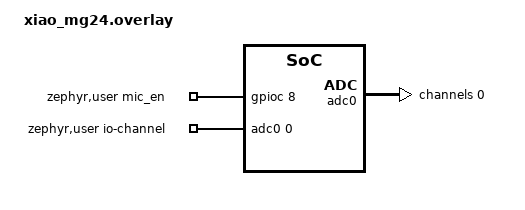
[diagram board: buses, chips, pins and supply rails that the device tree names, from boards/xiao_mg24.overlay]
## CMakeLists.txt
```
cmake_minimum_required(VERSION 3.20.0)
find_package(Zephyr REQUIRED HINTS $ENV{ZEPHYR_BASE})

project(adc_02)

target_sources(app PRIVATE src/main.c)
```

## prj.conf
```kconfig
CONFIG_GPIO=y
CONFIG_ADC=y

CONFIG_PRINTK=y
CONFIG_CONSOLE=y
CONFIG_SERIAL=y
```

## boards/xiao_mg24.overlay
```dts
/ {
    zephyr,user {
        io-channels = <&adc0 0>;
        mic_en_gpios = <&gpioc 8 GPIO_ACTIVE_HIGH>;
    };
};

&adc0 {
    status = "okay";
    #address-cells = <1>;
    #size-cells = <0>;

    channel@0 {
        reg = <0>;
        zephyr,acquisition-time = <ADC_ACQ_TIME_DEFAULT>;
        zephyr,gain = "ADC_GAIN_1";
        zephyr,input-positive = <IADC_INPUT_PC9>;
        zephyr,reference = "ADC_REF_VDD_1";
        zephyr,resolution = <12>;
        zephyr,vref-mv = <3300>;
    };
};
```

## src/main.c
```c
#include <zephyr/kernel.h>
#include <zephyr/device.h>
#include <zephyr/drivers/gpio.h>
#include <zephyr/drivers/adc.h>
#include <zephyr/sys/printk.h>

#define USER_NODE DT_PATH(zephyr_user)

#if !DT_NODE_EXISTS(USER_NODE)
#error "zephyr,user node missing"
#endif

static const struct gpio_dt_spec mic_en = GPIO_DT_SPEC_GET(USER_NODE, mic_en_gpios);
static const struct adc_dt_spec  mic_adc = ADC_DT_SPEC_GET(USER_NODE);

int main(void)
{
    int ret;
    int32_t mv;
    int16_t sample_buf;

    printk("\n--- Analog MIC (ADC) example ---\n");

    if (!device_is_ready(mic_en.port)) {
        printk("MIC_EN GPIO not ready\n");
        return 0;
    }

    if (!adc_is_ready_dt(&mic_adc)) {
        printk("ADC not ready\n");
        return 0;
    }

    ret = gpio_pin_configure_dt(&mic_en, GPIO_OUTPUT_INACTIVE);
    if (ret) {
        printk("gpio_pin_configure_dt failed: %d\n", ret);
        return 0;
    }

    gpio_pin_set_dt(&mic_en, 1);
    k_sleep(K_MSEC(50));

    ret = adc_channel_setup_dt(&mic_adc);
    if (ret) {
        printk("adc_channel_setup_dt failed: %d\n", ret);
        return 0;
    }

    struct adc_sequence sequence = {
        .buffer = &sample_buf,
        .buffer_size = sizeof(sample_buf),
    };

    while (1) {
        ret = adc_sequence_init_dt(&mic_adc, &sequence);
        if (ret) {
            printk("adc_sequence_init_dt failed: %d\n", ret);
            break;
        }

        ret = adc_read_dt(&mic_adc, &sequence);
        if (ret) {
            printk("adc_read_dt failed: %d\n", ret);
        } else {
            mv = sample_buf;
            ret = adc_raw_to_millivolts_dt(&mic_adc, &mv);
            if (ret < 0) {
                printk("raw=%d\n", sample_buf);
            } else {
                printk("raw=%d mv=%ld\n", sample_buf, (long)mv);
            }
        }

        k_sleep(K_MSEC(20));
    }

    return 0;
}
```
